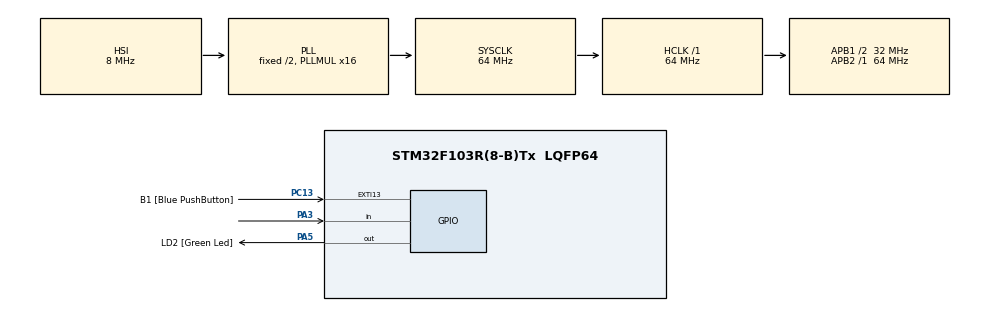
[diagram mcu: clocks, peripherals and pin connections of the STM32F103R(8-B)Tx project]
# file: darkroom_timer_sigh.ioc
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Mcu.Family=STM32F1
Mcu.Name=STM32F103R(8-B)Tx
Mcu.Package=LQFP64
NVIC.EXTI15_10_IRQn=true\:0\:0\:false\:false\:true\:true\:true\:true
NVIC.PriorityGroup=NVIC_PRIORITYGROUP_4
NVIC.TIM2_IRQn=true\:0\:0\:false\:false\:true\:true\:true\:true
PA13.GPIO_Label=TMS
PA13.Mode=Serial_Wire
PA13.Signal=SYS_JTMS-SWDIO
PA14.GPIO_Label=TCK
PA14.Mode=Serial_Wire
PA14.Signal=SYS_JTCK-SWCLK
PA2.GPIO_Label=USART_TX
PA2.GPIO_Mode=GPIO_MODE_AF_PP
PA2.GPIO_PuPd=GPIO_NOPULL
PA2.GPIO_Speed=GPIO_SPEED_FREQ_LOW
PA2.Signal=USART2_TX
PA3.Signal=GPIO_Input
PA5.GPIO_Label=LD2 [Green Led]
PA5.GPIO_ModeDefaultOutputPP=GPIO_MODE_OUTPUT_PP
PA5.GPIO_PuPd=GPIO_NOPULL
PA5.GPIO_Speed=GPIO_SPEED_FREQ_LOW
PA5.Signal=GPIO_Output
PB3.GPIO_Label=SWO
PB3.Signal=SYS_JTDO-TRACESWO
PC13-TAMPER-RTC.GPIO_Label=B1 [Blue PushButton]
PC13-TAMPER-RTC.GPIO_PuPd=GPIO_NOPULL
PC13-TAMPER-RTC.Signal=GPXTI13
PC14-OSC32_IN.Mode=LSE-External-Oscillator
PC14-OSC32_IN.Signal=RCC_OSC32_IN
PC15-OSC32_OUT.Mode=LSE-External-Oscillator
PC15-OSC32_OUT.Signal=RCC_OSC32_OUT
PD0-OSC_IN.Mode=HSE-External-Oscillator
PD0-OSC_IN.Signal=RCC_OSC_IN
PD1-OSC_OUT.Mode=HSE-External-Oscillator
PD1-OSC_OUT.Signal=RCC_OSC_OUT
ProjectManager.HeapSize=0x200
ProjectManager.StackSize=0x400
ProjectManager.TargetToolchain=STM32CubeIDE
RCC.AHBFreq_Value=64000000
RCC.APB1CLKDivider=RCC_HCLK_DIV2
RCC.APB1Freq_Value=32000000
RCC.APB1TimFreq_Value=64000000
RCC.APB2Freq_Value=64000000
RCC.APB2TimFreq_Value=64000000
RCC.HCLKFreq_Value=64000000
RCC.PLLMUL=RCC_PLL_MUL16
RCC.RTCClockSelection=RCC_RTCCLKSOURCE_LSE
RCC.SYSCLKFreq_VALUE=64000000
RCC.SYSCLKSource=RCC_SYSCLKSOURCE_PLLCLK
RCC.USBFreq_Value=64000000
TIM2.Period=7199
TIM2.Prescaler=999
VP_TIM2_VS_ClockSourceINT.Mode=Internal
board=NUCLEO-F103RB

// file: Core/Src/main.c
/* USER CODE BEGIN Header */
/**
  ******************************************************************************
  * @file           : main.c
  * @brief          : Main program body
  ******************************************************************************
  * @attention
  *
  * Copyright (c) 2024 STMicroelectronics.
  * All rights reserved.
  *
  * This software is licensed under terms that can be found in the LICENSE file
  * in the root directory of this software component.
  * If no LICENSE file comes with this software, it is provided AS-IS.
  *
  ******************************************************************************
  */
/* USER CODE END Header */
#include "main.h"

TIM_HandleTypeDef htim2;

TIM_HandleTypeDef htim2;
void SystemClock_Config(void);
static void MX_GPIO_Init(void);
static void MX_TIM2_Init(void);

int main(void)
{

  /* MCU Configuration--------------------------------------------------------*/

  /* Reset of all peripherals, Initializes the Flash interface and the Systick. */
  HAL_Init();
  SystemClock_Config();
  MX_GPIO_Init();
  MX_TIM2_Init();

  /* USER CODE BEGIN Init */

  	 //Pins
  	char relay[] = "A6";
	char time_selection[] = "A5";
	char time_focus[] = "A4";
	char start[] = "A3";
	char dial1[] = "A2";
	char dial2[] = "A1";

	//Settings
	int timer[] = {0,0,0,0};
	int timeOrFocus = 0; // 0 = time 1 = focus
	int timeTypes[] = {0,1,2}; // 0 = mili , 1 = seconds, 2 = minutes
	int timeUnit = 0 ;
	int timeIndex = 0;
	int status = 0;

  /* USER CODE END Init */

  /* Configure the system clock */
  SystemClock_Config();

  /* Initialize all configured peripherals */
  MX_GPIO_Init();
  MX_TIM2_Init();

  /* Infinite loop */
  while (1)
    {

	  //Buttons
  	  if(HAL_GPIO_ReadPin(GPIOA, start) == 1){
  		  status = flip(status);
  	  }

  	  if(HAL_GPIO_ReadPin(GPIOA, time_focus) == 1){
  		  timeOrFocus = flip(timeOrFocus);
  	  }

  	  if(HAL_GPIO_ReadPin(GPIOA, time_selection) == 1){
  		  timeIndex++;

  		  if(timeIndex > 2 ){
  			  timeIndex = 0;
  		  }

  		  timeUnit = timeType[timeIndex];

  	  }

  	  if(status == 0){

  		  switch(timeOrFocus){

  			  	  //time
  				  case 0:

  				  break;

  				  //focus
  				  case 1:
  					  HAL_GPIO_WritePin(GPIOD, relay, GPIO_PIN_SET);
  				  break;
  			  }
  	  }
  	  else{
  		  HAL_GPIO_WritePin(GPIOD, relay, GPIO_PIN_RESET);
  	  }

    }
 }

void flip(int a)
{
	if( a == 0){
		a = 1;
	}
	else{
		a = 0;
	}
	return a;
 }

//not sure if this code block belongs here

void MX_TIM2_Init(void)
{
    htim2.Instance = TIM2;
    htim2.Init.Prescaler = 999;  // Prescale value to make clock 1 kHz (assuming 1 MHz base clock)
    htim2.Init.CounterMode = TIM_COUNTERMODE_UP;
    htim2.Init.Period = 5000 - 1;  // Set for 5 seconds (5000 ms)
    htim2.Init.ClockDivision = TIM_CLOCKDIVISION_DIV1;
    htim2.Init.AutoReloadPreload = TIM_AUTORELOAD_PRELOAD_DISABLE;
    if (HAL_TIM_Base_Init(&htim2) != HAL_OK)
    {
        Error_Handler();
    }
}
void SystemClock_Config(void)
{
  RCC_OscInitTypeDef RCC_OscInitStruct = {0};
  RCC_ClkInitTypeDef RCC_ClkInitStruct = {0};

  /** Initializes the RCC Oscillators according to the specified parameters
  * in the RCC_OscInitTypeDef structure.
  */
  RCC_OscInitStruct.OscillatorType = RCC_OSCILLATORTYPE_HSI;
  RCC_OscInitStruct.HSIState = RCC_HSI_ON;
  RCC_OscInitStruct.HSICalibrationValue = RCC_HSICALIBRATION_DEFAULT;
  RCC_OscInitStruct.PLL.PLLState = RCC_PLL_ON;
  RCC_OscInitStruct.PLL.PLLSource = RCC_PLLSOURCE_HSI_DIV2;
  RCC_OscInitStruct.PLL.PLLMUL = RCC_PLL_MUL16;
  if (HAL_RCC_OscConfig(&RCC_OscInitStruct) != HAL_OK)
  {
    Error_Handler();
  }

  /** Initializes the CPU, AHB and APB buses clocks
  */
  RCC_ClkInitStruct.ClockType = RCC_CLOCKTYPE_HCLK|RCC_CLOCKTYPE_SYSCLK
                              |RCC_CLOCKTYPE_PCLK1|RCC_CLOCKTYPE_PCLK2;
  RCC_ClkInitStruct.SYSCLKSource = RCC_SYSCLKSOURCE_PLLCLK;
  RCC_ClkInitStruct.AHBCLKDivider = RCC_SYSCLK_DIV1;
  RCC_ClkInitStruct.APB1CLKDivider = RCC_HCLK_DIV2;
  RCC_ClkInitStruct.APB2CLKDivider = RCC_HCLK_DIV1;

  if (HAL_RCC_ClockConfig(&RCC_ClkInitStruct, FLASH_LATENCY_2) != HAL_OK)
  {
    Error_Handler();
  }
}

static void MX_TIM2_Init(void)
{

  TIM_ClockConfigTypeDef sClockSourceConfig = {0};
  TIM_MasterConfigTypeDef sMasterConfig = {0};

  htim2.Instance = TIM2;
  htim2.Init.Prescaler = 999;
  htim2.Init.CounterMode = TIM_COUNTERMODE_UP;
  htim2.Init.Period = 7199;
  htim2.Init.ClockDivision = TIM_CLOCKDIVISION_DIV1;
  htim2.Init.AutoReloadPreload = TIM_AUTORELOAD_PRELOAD_DISABLE;
  if (HAL_TIM_Base_Init(&htim2) != HAL_OK)
  {
    Error_Handler();
  }
  sClockSourceConfig.ClockSource = TIM_CLOCKSOURCE_INTERNAL;
  if (HAL_TIM_ConfigClockSource(&htim2, &sClockSourceConfig) != HAL_OK)
  {
    Error_Handler();
  }
  sMasterConfig.MasterOutputTrigger = TIM_TRGO_RESET;
  sMasterConfig.MasterSlaveMode = TIM_MASTERSLAVEMODE_DISABLE;
  if (HAL_TIMEx_MasterConfigSynchronization(&htim2, &sMasterConfig) != HAL_OK)
  {
    Error_Handler();
  }

}

static void MX_GPIO_Init(void)
{
  GPIO_InitTypeDef GPIO_InitStruct = {0};

  /* GPIO Ports Clock Enable */
  __HAL_RCC_GPIOC_CLK_ENABLE();
  __HAL_RCC_GPIOD_CLK_ENABLE();
  __HAL_RCC_GPIOA_CLK_ENABLE();
  __HAL_RCC_GPIOB_CLK_ENABLE();

  /*Configure GPIO pin Output Level */
  HAL_GPIO_WritePin(LD2_GPIO_Port, LD2_Pin, GPIO_PIN_RESET);

  /*Configure GPIO pin : B1_Pin */
  GPIO_InitStruct.Pin = B1_Pin;
  GPIO_InitStruct.Mode = GPIO_MODE_IT_RISING;
  GPIO_InitStruct.Pull = GPIO_NOPULL;
  HAL_GPIO_Init(B1_GPIO_Port, &GPIO_InitStruct);

  /*Configure GPIO pin : USART_TX_Pin */
  GPIO_InitStruct.Pin = USART_TX_Pin;
  GPIO_InitStruct.Mode = GPIO_MODE_AF_PP;
  GPIO_InitStruct.Speed = GPIO_SPEED_FREQ_LOW;
  HAL_GPIO_Init(USART_TX_GPIO_Port, &GPIO_InitStruct);

  /*Configure GPIO pin : PA3 */
  GPIO_InitStruct.Pin = GPIO_PIN_3;
  GPIO_InitStruct.Mode = GPIO_MODE_INPUT;
  GPIO_InitStruct.Pull = GPIO_NOPULL;
  HAL_GPIO_Init(GPIOA, &GPIO_InitStruct);

  /*Configure GPIO pin : LD2_Pin */
  GPIO_InitStruct.Pin = LD2_Pin;
  GPIO_InitStruct.Mode = GPIO_MODE_OUTPUT_PP;
  GPIO_InitStruct.Pull = GPIO_NOPULL;
  GPIO_InitStruct.Speed = GPIO_SPEED_FREQ_LOW;
  HAL_GPIO_Init(LD2_GPIO_Port, &GPIO_InitStruct);

  /* EXTI interrupt init*/
  HAL_NVIC_SetPriority(EXTI15_10_IRQn, 0, 0);
  HAL_NVIC_EnableIRQ(EXTI15_10_IRQn);

}

void Error_Handler(void)
{
  __disable_irq();
  while (1)
  {
  }
}
